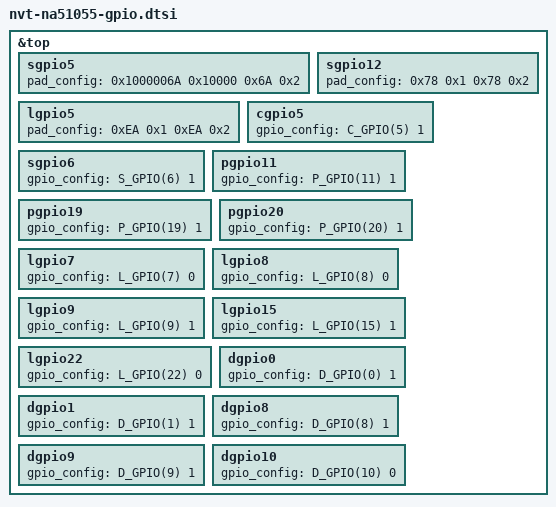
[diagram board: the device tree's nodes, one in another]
&top {
sgpio5{pad_config = <0x1000006A 0x10000 0x6A 0x2>;};/*TVI_DET*/
sgpio12{pad_config = <0x78 0x1 0x78 0x2>;};/*LCD_ID0*/
lgpio5{pad_config = <0xEA 0x1 0xEA 0x2>;};/*SOS_KEY*/
cgpio5{gpio_config = <C_GPIO(5) 1>;};/*TVI_PWR*/
sgpio6{gpio_config = <S_GPIO(6) 1>;};/*SN1_RESET*/
pgpio11{gpio_config = <P_GPIO(11) 1>;};/*TVI_REST*/
pgpio19{gpio_config = <P_GPIO(19) 1>;};/*SN1_18*/
pgpio20{gpio_config = <P_GPIO(20) 1>;};/*WIFI_PWR*/
lgpio7{gpio_config = <L_GPIO(7) 0>;};/*LED_WIFI*/
lgpio8{gpio_config = <L_GPIO(8) 0>;};/*LED_BUSY*/
lgpio9{gpio_config = <L_GPIO(9) 1>;};/*SN1_29*/
lgpio15{gpio_config = <L_GPIO(15) 1>;};/*LCD_RST*/
lgpio22{gpio_config = <L_GPIO(22) 0>;};/*APAMP_EN*/
dgpio0{gpio_config = <D_GPIO(0) 1>;};/*WL_REG_ON*/
dgpio1{gpio_config = <D_GPIO(1) 1>;};/*SD_PWR*/
dgpio8{gpio_config = <D_GPIO(8) 1>;};/*BT_DEV_WAKE*/
dgpio9{gpio_config = <D_GPIO(9) 1>;};/*BT_RST*/
dgpio10{gpio_config = <D_GPIO(10) 0>;};/*LCD_BL*/
};
